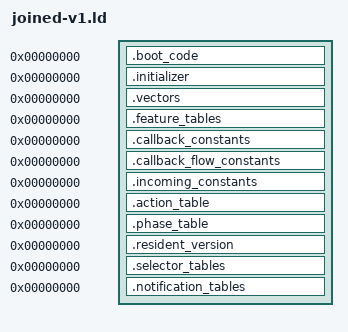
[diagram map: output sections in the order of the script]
OUTPUT_ARCH(riscv)
SECTIONS
{
 .boot_code 0 : SUBALIGN(2) { *(.boot_code)
  *(.text.tsl9_feature_external_abc4)
  *(.text.tsl9_settings_state_inputs_block_abce)
  *(.text.tsl9_settings_state_inputs_block_abe0)
  *(.text.tsl9_settings_state_inputs_block_abe2)
  *(.text.tsl9_settings_state_inputs_block_abea)
  *(.text.tsl9_settings_state_inputs_block_abf0)
  *(.text.tsl9_feature_external_b14a)
  *(.text.tsl9_settings_state_inputs_block_b150)
  *(.text.tsl9_settings_state_inputs_block_b174)
  *(.text.tsl9_record_dispatch_provider_b176)
  *(.text.tsl9_settings_state_inputs_block_b182)
  *(.text.tsl9_settings_state_inputs_block_b188)
  *(.text.tsl9_settings_state_inputs_block_b192)
  *(.text.tsl9_settings_state_inputs_block_b196)
  *(.text.tsl9_settings_state_inputs_block_b19c)
  *(.text.tsl9_settings_state_inputs_block_b1a8)
  *(.text.tsl9_settings_state_inputs_block_b1ae)
  *(.text.tsl9_feature_external_b1b6)
  *(.text.tsl9_settings_state_inputs_block_b1c4)
  *(.text.tsl9_settings_state_inputs_block_b1d8)
  *(.text.tsl9_settings_state_inputs_block_b1de)
  *(.text.tsl9_settings_state_inputs_block_b1f0)
  *(.text.tsl9_settings_state_inputs_block_b200)
  *(.text.tsl9_settings_state_inputs_block_b20c)
  *(.text.tsl9_settings_state_inputs_block_b212)
  *(.text.tsl9_settings_state_inputs_block_b21e)
  *(.text.tsl9_record_dispatch_provider_b220)
  *(.text.tsl9_main_services_provider_b242)
  *(.text.tsl9_settings_state_inputs_entry_b254)
  *(.text.tsl9_settings_state_inputs_block_b264)
  *(.text.tsl9_settings_state_inputs_block_b270)
  *(.text.tsl9_settings_state_inputs_block_b288)
  *(.text.tsl9_settings_state_inputs_block_b298)
  *(.text.tsl9_settings_state_inputs_entry_b29a)
  *(.text.tsl9_settings_state_inputs_block_b2a2)
  *(.text.tsl9_settings_state_inputs_block_b2a4)
  *(.text.tsl9_settings_state_inputs_block_b2a8)
  *(.text.tsl9_settings_state_inputs_block_b2aa)
  *(.text.tsl9_settings_state_inputs_block_b2d8)
  *(.text.tsl9_settings_state_inputs_block_b2f8)
  *(.text.tsl9_feature_external_b2fe)
  *(.text.tsl9_settings_state_inputs_block_b316)
  *(.text.tsl9_settings_state_inputs_block_b31c)
  *(.text.tsl9_settings_state_inputs_block_b322)
  *(.text.tsl9_settings_state_inputs_block_b328)
  *(.text.tsl9_settings_state_inputs_block_b32e)
  *(.text.tsl9_settings_state_inputs_block_b336)
  *(.text.tsl9_settings_state_inputs_block_b33c)
  *(.text.tsl9_settings_state_inputs_block_b340)
  *(.text.tsl9_settings_state_inputs_block_b364)
  *(.text.tsl9_settings_state_inputs_block_b370)
  *(.text.tsl9_feature_external_b372)
  *(.text.tsl9_settings_state_inputs_block_b382)
  *(.text.tsl9_settings_state_inputs_block_b38e)
  *(.text.tsl9_feature_external_cf96)
  *(.text.tsl9_settings_state_inputs_block_cfb0)
  *(.text.tsl9_settings_state_inputs_block_cfc8)
  *(.text.tsl9_settings_state_inputs_block_cfd4)
  *(.text.tsl9_settings_state_inputs_block_cfe0)
  *(.text.tsl9_settings_state_inputs_block_cff4)
  *(.text.tsl9_settings_state_inputs_block_cffc)
  *(.text.tsl9_settings_state_inputs_block_d00c)
  *(.text.tsl9_settings_state_inputs_block_d022)
  *(.text.tsl9_settings_state_inputs_block_d026)
  *(.text.tsl9_settings_state_inputs_block_d030)
  *(.text.tsl9_settings_state_inputs_block_d036)
  *(.text.tsl9_settings_state_inputs_block_d03a)
  *(.text.tsl9_settings_state_inputs_block_d03e)
  *(.text.tsl9_settings_state_inputs_block_d040)
  *(.text.tsl9_feature_external_d104)
  *(.text.tsl9_settings_state_inputs_block_d11c)
  *(.text.tsl9_settings_state_inputs_block_d124)
  *(.text.tsl9_settings_state_inputs_block_d12c)
  *(.text.tsl9_settings_state_inputs_block_d134)
  *(.text.tsl9_settings_state_inputs_block_d148)
  *(.text.tsl9_feature_external_f0d0)
  *(.text.tsl9_settings_state_inputs_block_f0e4)
  *(.text.tsl9_settings_state_inputs_block_f0ec)
  *(.text.tsl9_settings_state_inputs_block_f0fe)
  *(.text.tsl9_settings_state_inputs_block_f10a)
  *(.text.tsl9_settings_state_inputs_block_f118)
  *(.text.tsl9_settings_state_inputs_block_f11e)
  *(.text.tsl9_settings_state_inputs_block_f126)
  *(.text.tsl9_settings_state_inputs_block_f12a)
  *(.text.tsl9_settings_state_inputs_block_f132)
  *(.text.tsl9_settings_state_inputs_block_f138)
  *(.text.tsl9_settings_state_inputs_block_f13e)
  *(.text.tsl9_settings_state_inputs_block_f142)
  *(.text.tsl9_settings_state_inputs_block_f148)
  *(.text.tsl9_feature_external_f14a)
  *(.text.tsl9_settings_state_inputs_block_f164)
  *(.text.tsl9_settings_state_inputs_block_f16e)
  *(.text.tsl9_settings_state_inputs_block_f172)
  *(.text.tsl9_settings_state_inputs_block_f182)
  *(.text.tsl9_settings_state_inputs_block_f196)
  *(.text.tsl9_settings_state_inputs_block_f1aa)
  *(.text.tsl9_settings_state_inputs_block_f1ba)
 }
 .initializer 0 : SUBALIGN(4) { *(.initializer) }
 .vectors 0 : SUBALIGN(4) { *(.vectors) }
 .feature_tables 0 : SUBALIGN(4) { *(.feature_tables) }
 .callback_constants 0 : SUBALIGN(4) { *(.callback_constants) }
 .callback_flow_constants 0 : SUBALIGN(4) { *(.callback_flow_constants) }
 .incoming_constants 0 : SUBALIGN(4) { *(.incoming_constants) }
 .action_table 0 : SUBALIGN(4) { *(.action_table) }
 .phase_table 0 : SUBALIGN(4) { *(.phase_table) }
 .resident_version 0 : SUBALIGN(4) { *(.resident_version) }
 .selector_tables 0 : SUBALIGN(1) {
  *(.rodata.tsl9_feature_state_records_static_data_1a4e4)
  *(.rodata.tsl9_feature_state_records_static_data_1a518)
  *(.rodata.tsl9_feature_state_records_static_data_1a528)
  *(.rodata.tsl9_feature_state_records_static_data_1a538)
 }
 .notification_tables 0 : SUBALIGN(4) {
  *(.rodata.tsl9_selector_notifications_table_1a13c)
  *(.rodata.tsl9_selector_notifications_table_1a150)
  *(.rodata.tsl9_selector_notifications_table_1a1c8)
  *(.rodata.tsl9_selector_notifications_table_1a314)
  *(.rodata.tsl9_selector_notifications_table_1a33c)
 }
 /DISCARD/ : { *(.comment) *(.riscv.attributes) *(.llvm_addrsig) }
}
